# S6E2CCxJ register map
Vendor: Cypress; File version: 2.1
CPU: CM4 r0p1, little endian, MPU, FPU, 4 interrupt priority bits
Registers are 32-bit, read-write, reset 0x0 unless marked. A register's access mark holds for its fields unless they carry their own. Offsets are from the block's base; [hi:lo] are bit positions; {n}, {i} and the like mark numbered series; 'fields as' and 'values as' point back to an identical list.

## ETHERNET_MAC0
Base 0x40064000
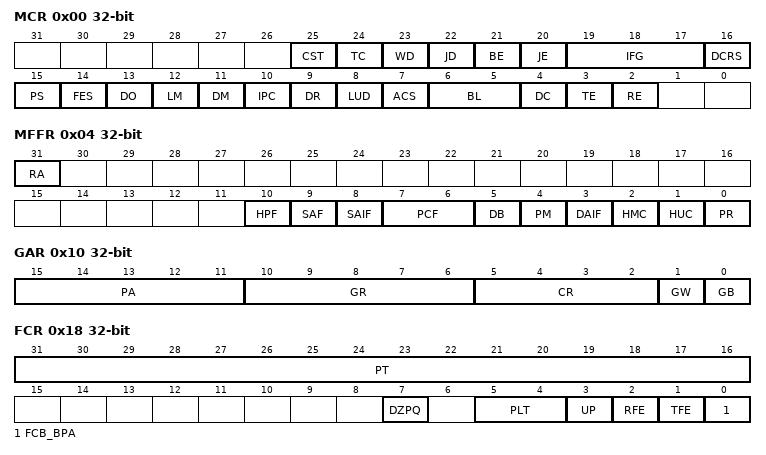
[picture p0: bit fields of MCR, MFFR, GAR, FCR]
0x00 MCR — MAC Configuration Register [BHW]
  [25] CST — CRC stripping for Type frames
  [24] TC — Transmit Configuration in RGMII
  [23] WD — Watchdog Disable
  [22] JD — Jabber Disable
  [21] BE — Frame Burst Enable
  [20] JE — Jumbo Frame Enable
  [19:17] IFG — Inter-Frame GAP
  [16] DCRS — Disable Carrier Sense During Transaction
  [15] PS — Port Select
  [14] FES — Speed
  [13] DO — Disable Receive Own
  [12] LM — Loop-back Mode
  [11] DM — Duplex mode
  [10] IPC — Checksum Offload
  [9] DR — Disable Retry
  [8] LUD — Link Up/Down in RGMII
  [7] ACS — Automatic Pad/CRC Stripping
  [6:5] BL — Back-off Limit
  [4] DC — Deferral Check
  [3] TE — Transmitter Enable
  [2] RE — Receiver Enable
0x04 MFFR — MAC Frame Filter Register [BHW]
  [31] RA — Receive All
  [10] HPF — Hash or Perfect Filter
  [9] SAF — Source Address Filter
  [8] SAIF — Source Address Inverse Filter
  [7:6] PCF — Pass Control Frames
  [5] DB — Disable Broadcast Frames
  [4] PM — Pass All Multicast
  [3] DAIF — DA Inverse Filtering
  [2] HMC — Hash Multicast
  [1] HUC — Hash Unicast
  [0] PR — Promiscuous Mode
0x08 MHTRH — MAC Hash Table Register (High) [BHW]
  [31:0] HTH — the upper 32 bits of the hash table in the HTH
0x0C MHTRL — MAC Hash Table Register (Low) [BHW]
  [31:0] HTL — the lower 32 bits of the hash table in the HTL
0x10 GAR — GMII/MII Address Register [BHW]
  [15:11] PA — Physical Layer Address
  [10:6] GR — GMII Register
  [5:2] CR — Application Clock Range
  [1] GW — GMII/MII Write
  [0] GB — GMII/MII Busy
0x14 GDR — GMII/MII Data Register [BHW]
  [15:0] GD — GMII/MII Data Register
0x18 FCR — Flow Control Register [BHW]
  [31:16] PT — Pause Time
  [7] DZPQ — Disable Zero-Quanta Pause
  [5:4] PLT — Pause Low Threshold
  [3] UP — Unicast Pause Frame detect
  [2] RFE — Receive Flow Control Enable
  [1] TFE — Transmit Flow Control Enable
  [0] FCB_BPA — Flow Control Busy/Backpressure Activate
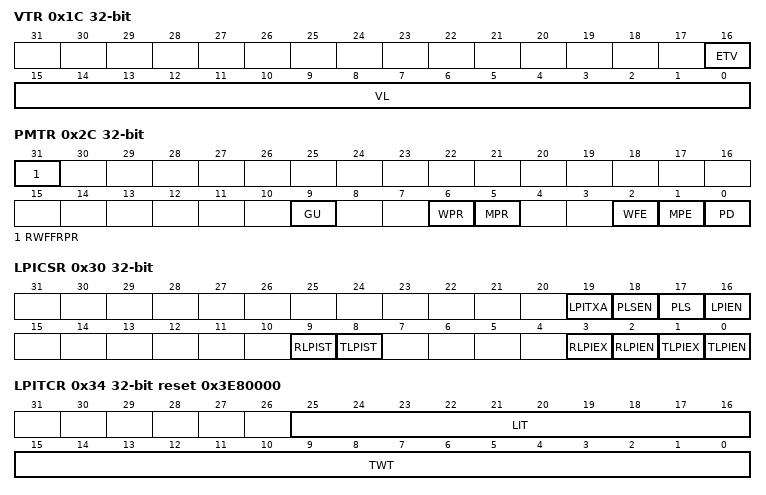
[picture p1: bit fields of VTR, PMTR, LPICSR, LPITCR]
0x1C VTR — VLAN TAG Register [BHW]
  [16] ETV — Enable 12-Bit VLAN Tag Comparison
  [15:0] VL — VLAN Tag Identifier
0x28 RWFFR — Remote Wake-up Frame Filter Register [BHW]
  [31:0] RWFFR — Remote Wake-up Frame Filter Register
0x2C PMTR — PMT Register [BHW]
  [31] RWFFRPR — Remote Wake-up Frame Filter Register Pointer Reset
  [9] GU — Global Unicast
  [6] WPR ro — Wake Up Frame Receive
  [5] MPR ro — Magic Packet Received
  [2] WFE — Wake-Up Frame Enable
  [1] MPE — Magic Packet Enable
  [0] PD — Power Down
0x30 LPICSR — LPI Control and Status Register [BHW]
  [19] LPITXA — LPI TX Automate
  [18] PLSEN — PHY Link Status Enable
  [17] PLS — PHY Link Status
  [16] LPIEN — LPI Enable
  [9] RLPIST ro — Receive LPI State
  [8] TLPIST ro — Transmit LPI State
  [3] RLPIEX ro — Receive LPI Exit
  [2] RLPIEN ro — Receive LPI Entry
  [1] TLPIEX ro — Transmit LPI Exit
  [0] TLPIEN ro — Transmit LPI Entry
0x34 LPITCR reset 0x3E80000 — LPI Timers Control Register [BHW]
  [25:16] LIT — LPI LS TIMER
  [15:0] TWT — LPI TW TIMER
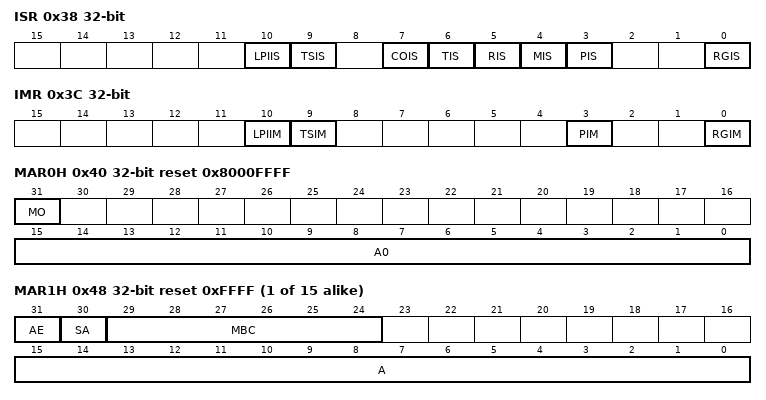
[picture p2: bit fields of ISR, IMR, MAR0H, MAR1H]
0x38 ISR ro — Interrupt Status Register [BHW]
  [10] LPIIS — LPI Interrupt Status
  [9] TSIS — Time Stamp Interrupt Status
  [7] COIS — MMC Receive Checksum Offload Interrupt Status
  [6] TIS — MMC Transmit Interrupt Status
  [5] RIS — MMC Receive Interrupt Status
  [4] MIS — MMC Interrupt Status
  [3] PIS — PMT Interrupt Status
  [0] RGIS — RGMII Interrupt Status
0x3C IMR — Interrupt Mask Register [BHW]
  [10] LPIIM — LPI Interrupt Mask
  [9] TSIM — Time Stamp Interrupt Mask
  [3] PIM — PMT Interrupt Mask
  [0] RGIM — RGMII Interrupt Mask
0x40 MAR0H reset 0x8000FFFF — MAC Address0 Register (High) [BHW]
  [31] MO ro — Must be one
  [15:0] A0 — MAC Address0
0x44 MAR0L reset 0xFFFFFFFF — MAC Address0 Register (Low) [BHW]
  [31:0] A0 — MAC Address0
{0x40+8i} MAR{i}H reset 0xFFFF (i=1..15) — MAC Address{i} Register -High [BHW]
  [31] AE — Address Enable
  [30] SA — Source Address
  [29:24] MBC — Mask Byte Control
  [15:0] A — MAC Address
{0x44+8i} MAR{i}L reset 0xFFFFFFFF (i=1..15) — MAC Address{i} Register -Low [BHW]
  [31:0] A — MAC Address
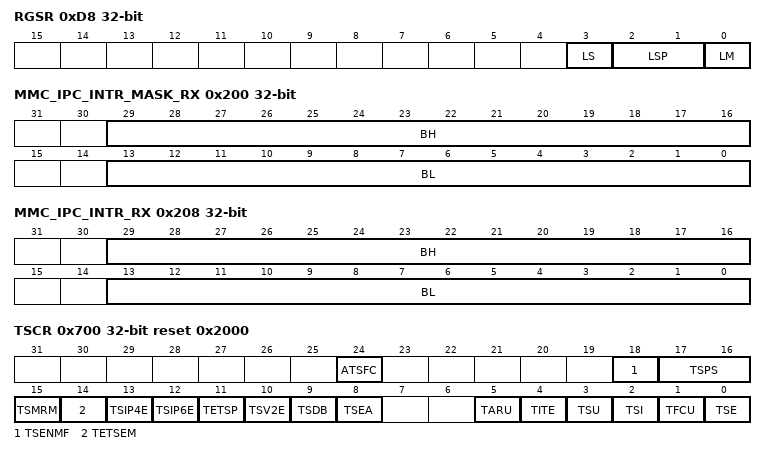
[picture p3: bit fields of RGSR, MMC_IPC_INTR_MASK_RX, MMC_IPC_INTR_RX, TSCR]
0xD8 RGSR ro — RGMII Status Register) [BHW]
  [3] LS — Link Status
  [2:1] LSP — Link Speed
  [0] LM — Link Mode
0x100 MMC_CNTL — MMC Control Register [BHW]
  [5:0] B — Bits of MMC_CNTL
0x104 MMC_INTR_RX ro — Receive Interrupt Register [BHW]
  [23:0] B rw — Bits of MMC_INTR_RX
0x108 MMC_INTR_TX ro — MMC Transmit Interrupt Register [BHW]
  [24:0] B rw — Bits of MMC_INTR_TX
0x10C MMC_INTR_MASK_RX — MMC Receive Interrupt Mask Register [BHW]
  [23:0] B — Bits of MMC_INTR_MASK_RX
0x110 MMC_INTR_MASK_TX — MMC Transmit Interrupt Mask Register [BHW]
  [24:0] B — Bits of MMC_INTR_MASK_TX
0x114 TXOCTETCOUNT_GB ro — Number of bytes transmitted (exclusive of preamble and retried bytes) in good and bad frames [BHW]
0x118 TXFRAMECOUNT_GB ro — Number of good and bad frames transmitted exclusive of retried frames [BHW]
0x11C TXBROADCASTFRAMES_G ro — Number of good broadcast frames transmitted [BHW]
0x120 TXMULTICASTFRAMES_G ro — Number of good multicast frames transmitted[BHW]
0x124 TX64OCTETS_GB ro — Number of good and bad frames transmitted with length of 64 bytes exclusive of preamble and retried frames [BHW]
0x128 TX65TO127OCTETS_GB ro — Number of good and bad frames transmitted with length between 65 and 127 (inclusive) bytes exclusive of preamble and retried frames [BHW]
0x12C TX128TO255OCTETS_GB ro — Number of good and bad frames transmitted with length between 128 and 255 (inclusive) bytes exclusive of preamble and retried frames [BHW]
0x130 TX256TO511OCTETS_GB ro — Number of good and bad frames transmitted with length between 256 and 511 (inclusive) bytes exclusive of preamble and retried frames [BHW]
0x134 TX512TO1023OCTETS_GB ro — Number of good and bad frames transmitted with length between 512 and 1023 (inclusive) bytes exclusive of preamble and retried frames [BHW]
0x138 TX1024TOMAXOCTETS_GB ro — Number of good and bad frames transmitted with length between 1024 and Maxsize (inclusive) bytes exclusive of preamble and retried frames [BHW]
0x13C TXUNICASTFRAMES_GB ro — Number of good and bad unicast frames transmitted [BHW]
0x140 TXMULTICASTFRAMES_GB ro — Number of good and bad multicast frames transmitted [BHW]
0x144 TXBROADCASTFRAMES_GB ro — Number of good and bad broadcast frames transmitted [BHW]
0x148 TXUNDERFLOWERROR ro — Number of frames aborted due to frame underflow error [BHW]
0x14C TXSINGLECOL_G ro — Number of successfully transmitted frames after a single collision in Half-duplex mode [BHW]
0x150 TXMULTICOL_G ro — Number of successfully transmitted frames after more than a single collision in Half-duplex mode [BHW]
0x154 TXDEFERRED ro — Number of successfully transmitted frames after a deferral in Half-duplex mode [BHW]
0x158 TXLATECOL ro — Number of frames aborted due to late collision error [BHW]
0x15C TXEXESSCOL ro — Number of frames aborted due to excessive (16) collision errors [BHW]
0x160 TXCARRIERERROR ro — Number of frames aborted due to carrier sense error (no carrier or loss of carrier). [BHW]
0x164 TXOCTETCOUNT_G ro — Number of bytes transmitted (exclusive of preamble) in good frames only [BHW]
0x168 TXFRAMECOUNT_G ro — Number of good frames transmitted [BHW]
0x16C TXEXECESSDEF_G ro — Number of frames aborted due to excessive deferral error (deferred for more than two max-sized frame times) [BHW]
0x170 TXPAUSEFRAMES ro — Number of good PAUSE frames transmitted [BHW]
0x174 TXVLANFRAMES_G ro — Number of good VLAN frames transmitted exclusive of retried frames [BHW]
0x180 RXFRAMECOUNT_GB ro — Number of good and bad frames received [BHW]
0x184 RXOCTETCOUNT_GB ro — Number of bytes received (exclusive of preamble) in good and bad frames. [BHW]
0x188 RXOCTETCOUNT_G ro — Number of bytes received (exclusive of preamble) only in good frames [BHW]
0x18C RXBROADCASTFRAMES_G ro — Number of good broadcast frames received [BHW]
0x190 RXMULTICASTFRAMES_G ro — Number of good multicast frames received [BHW]
0x194 RXCRCERROR ro — Number of frames received with CRC error[BHW]
0x198 RXALLIGNMENTERROR ro — Number of frames received with alignment (dribble) error. Valid only in 10/100 mode [BHW]
0x19C RXRUNTERROR ro — Number of frames received with runt (64 bytes and CRC error) error [BHW]
0x1A0 RXJABBERERROR ro — Number of frames received with length greater than 1518 bytes with CRC error [BHW]
0x1A4 RXUNDERSIZE_G ro — Number of frames received with length less than 64 bytes without any errors. [BHW]
0x1A8 RXOVERSIZE_G ro — Number of frames received with length greater than the maxsize without error [BHW]
0x1AC RX64OCTETS_GB ro — Number of good and bad frames received with length 64 bytes exclusive of preamble [BHW]
0x1B0 RX65TO127OCTETS_GB ro — Number of good and bad frames received with length between 65 and 127 (inclusive) bytes exclusive of preamble. [BHW]
0x1B4 RX128TO255OCTETS_GB ro — Number of good and bad frames received with length between 128 and 255 (inclusive) bytes exclusive of preamble. [BHW]
0x1B8 RX256TO511OCTETS_GB ro — Number of good and bad frames received with length between 256 and 511 (inclusive) bytes exclusive of preamble. [BHW]
0x1BC RX512TO1023OCTETS_GB ro — Number of good and bad frames received with length between 512 and 1023 (inclusive) bytes exclusive of preamble. [BHW]
0x1C0 RX1024TOMAXOCTETS_GB ro — Number of good and bad frames received with length between 1024 and maxsize (inclusive) bytes exclusive of preamble [BHW]
0x1C4 RXUNICASTFRAMES_G ro — Number of good unicast frames received [BHW]
0x1C8 RXLENGTHERROR ro — Number of frames received with length error (Length type field is not the frame size) for all frames with valid length field [BHW]
0x1CC RXOUTOFRANGETYPE ro — Number of frames received with length/type field not equal to the valid frame size (Greater than 1500) [BHW]
0x1D0 RXPAUSEFRAMES ro — Number of good and valid PAUSE frames received [BHW]
0x1D4 RXFIFOOVERFLOW ro — Number of missed received frames due to FIFO overflow [BHW]
0x1D8 RXVLANFRAMES_GB ro — Number of good and bad VLAN frames received [BHW]
0x1DC RXWATCHDOGERROR ro — Number of frames received with error due to watchdog timeout error (frames with a data load larger than 2048 bytes) [BHW]
0x200 MMC_IPC_INTR_MASK_RX — MMC Receive Checksum Offload Interrupt Mask Register [BHW]
  [29:16] BH — Higher bits of MMC_IPC_INTR_MASK_RX
  [13:0] BL — Lower bits of MMC_IPC_INTR_MASK_RX
0x208 MMC_IPC_INTR_RX ro — MMC Receive Checksum Offload Interrupt Register [BHW]
  [29:16] BH rw — Higher bits of MMC_IPC_INTR_RX
  [13:0] BL rw — Lower bits of MMC_IPC_INTR_RX
0x210 RXIPV4_GD_FRMS ro — Number of good IPv4 datagrams received with the TCP/UDP or ICMP payload [BHW]
0x214 RXIPV4_HDRERR_FRMS ro — Number of IPv4 datagrams received with header errors (checksum/length or version mismatch) [BHW]
0x218 RXIPV4_NOPAY_FRMS ro — Number of IPv4 datagram frames received that did not have a TCP/UDP or ICMP payload processed by the Checksum engine [BHW]
0x21C RXIPV4_FRAG_FRMS ro — Number of good IPv4 datagrams with fragmentation [BHW]
0x220 RXIPV4_UDSBL_FRMS ro — Number of good IPv4 datagrams received that had a UDP payload with checksum disabled [BHW]
0x224 RXIPV6_GD_FRMS ro — Number of good IPv6 datagrams received with TCP/UDP or ICMP payloads [BHW]
0x228 RXIPV6_HDRERR_FRMS ro — Number of IPv6 datagrams received with header errors (length or version mismatch) [BHW]
0x22C RXIPV6_NOPAY_FRMS ro — Number of IPv6 datagram frames received that did not have a TCP/UDP or ICMP payload. This includes all IPv6 datagrams with fragmentation or security extension headers [BHW]
0x230 RXUDP_GD_FRMS ro — Number of good IP datagrams with a good UDP payload. This counter is not updated when the rxipv4_udsbl_frms counter is incremented [BHW]
0x234 RXUDP_ERR_FRMS ro — Number of good IP datagrams whose UDP payload has a checksum error [BHW]
0x238 RXTCP_GD_FRMS ro — Number of good IP datagrams with a good TCP payload [BHW]
0x23C RXTCP_ERR_FRMS ro — Number of good IP datagrams whose TCP payload has a checksum error [BHW]
0x240 RXICMP_GD_FRMS ro — Number of good IP datagrams with a good ICMP payload [BHW]
0x244 RXICMP_ERR_FRMS ro — Number of good IP datagrams whose ICMP payload has a checksum error [BHW]
0x250 RXIPV4_GD_OCTETS ro — Number of bytes received in good IPv4 datagrams encapsulating TCP/UDP or ICMP data. (Ethernet header/FCS/pad or IP pad bytes are not included in this counter or in the octet counters listed below). [BHW]
0x254 RXIPV4_HDRERR_OCTETS ro — Number of bytes received in IPv4 datagrams with header errors (checksum/length version mismatch). The value in the Length field of IPv4 header is used to update this counter [BHW]
0x258 RXIPV4_NOPAY_OCTETS ro — Number of bytes received in IPv4 datagrams that did not have a TCP/UDP or ICMP payload. The value in the IPv4 header's Length field is used to update this counter [BHW]
0x25C RXIPV4_FRAG_OCTETS ro — Number of bytes received in fragmented IPv4 datagrams. The value in the IPv4 header's Length field is used to update this counter [BHW]
0x260 RXIPV4_UDSBL_OCTETS ro — Number of bytes received in a UDP segment that had the UDP checksum disabled. This counter does not count IP Header bytes [BHW]
0x264 RXIPV6_GD_OCTETS ro — Number of bytes received in good IPv6 datagrams encapsulating TCP/UDP or ICMPv6 data [BHW]
0x268 RXIPV6_HDRERR_OCTETS ro — Number of bytes received in IPv6 datagrams with header errors (length/version mismatch). The value in the IPv6 header's Length field is used to update this counter. [BHW]
0x26C RXIPV6_NOPAY_OCTETS ro — Number of bytes received in IPv6 datagrams that did not have a TCP/UDP or ICMP payload. The value in the IPv6 header's Length field is used to update this counter [BHW]
0x270 RXUDP_GD_OCTETS ro — Number of bytes received in a good UDP segment. This counter (and the counters below) does not count IP header bytes [BHW]
0x274 RXUDP_ERR_OCTETS ro — Number of bytes received in a UDP segment that had checksum errors [BHW]
0x278 RXTCP_GD_OCTETS ro — Number of bytes received in a good TCP segment [BHW]
0x27C RXTCP_ERR_OCTETS ro — Number of bytes received in a TCP segment with checksum errors [BHW]
0x280 RXICMP_GD_OCTETS ro — Number of bytes received in a good ICMP segment [BHW]
0x284 RXICMP_ERR_OCTETS ro — Number of bytes received in an ICMP segment with checksum errors [BHW]
0x700 TSCR reset 0x2000 — Time Stamp Control Register [BHW]
  [24] ATSFC — Auxiliary Snapshot FIFO Clear
  [18] TSENMF — Enable MAC address for PTP frame filtering
  [17:16] TSPS — SelectPTP packets for taking snapshots
  [15] TSMRM — Enable Snapshot for Messages Relevant to Master
  [14] TETSEM — Enable Time Stamp Snapshot for Event Messages
  [13] TSIP4E — Enable Time Stamp Snapshot for IPv4 frames
  [12] TSIP6E — Enable Time Stamp Snapshot for IPv6 frames
  [11] TETSP — Enable Time Stamp Snapshot for PTP over Ethernet frames
  [10] TSV2E — Enable PTP packet snooping for version 2 format
  [9] TSDB — Time Stamp Digital or Binary rollover control
  [8] TSEA — Enable Time Stamp for All Frames
  [5] TARU — Addend Register Update
  [4] TITE — Time Stamp Interrupt Trigger Enable
  [3] TSU — Time Stamp Update
  [2] TSI — Time Stamp Initialize
  [1] TFCU — Time Stamp Fine or Coarse Update
  [0] TSE — Time Stamp Enable
0x704 SSIR — Sub-Second Increment Register [BHW]
  [7:0] SSINC — Sub-Second Increment Value
0x708 STSR ro — System Time - Seconds Register [BHW]
  [31:0] TSS — Time Stamp Second
0x70C STNR ro — System Time - Nanoseconds Register [BHW]
  [30:0] TSSS — Time Stamp Sub-Seconds
0x710 STSUR — System Time - Seconds Update Register [BHW]
  [31:0] TSS — Time Stamp Second
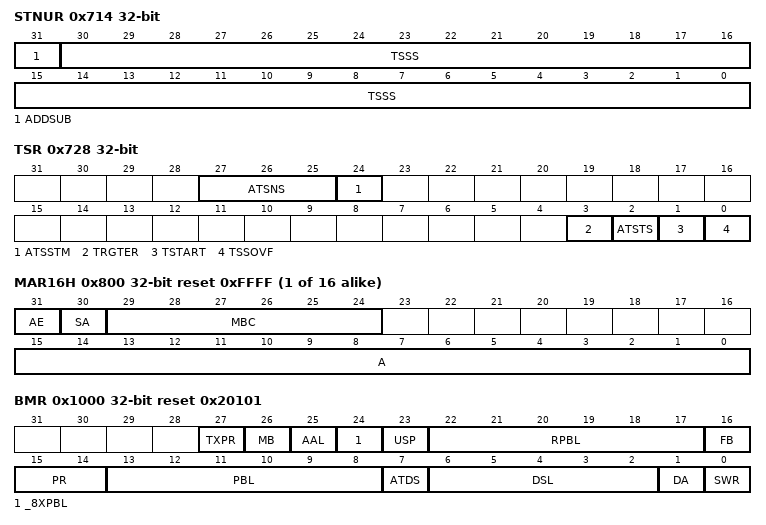
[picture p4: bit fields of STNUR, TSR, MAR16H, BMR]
0x714 STNUR — System Time - Nanoseconds Update Register [BHW]
  [31] ADDSUB — Add or Subtract Time
  [30:0] TSSS — Time Stamp Sub-Seconds
0x718 TSAR — Time Stamp Addend Register [BHW]
  [31:0] TSAR — Time Stamp Addend Register
0x71C TTSR — Target Time Seconds Register [BHW]
  [31:0] TSTR — Target Time Stamp Seconds Register
0x720 TTNR — Target Time Nanoseconds Register [BHW]
  [30:0] TSTR — Target Time Stamp Nanoseconds Register
0x724 STHWSR — System Time - Higher Word Seconds Register [BHW]
  [15:0] TSHWR — Time Stamp Higher Word Register
0x728 TSR ro — Time Stamp Status Register [BHW]
  [27:25] ATSNS — Auxiliary Time Stamp Number of Snapshots
  [24] ATSSTM — Auxiliary Time Stamp Snapshot Trigger Missed
  [3] TRGTER — Timestamp Target Time Error
  [2] ATSTS — Auxiliary Time Stamp Trigger Snapshot
  [1] TSTART — Time Stamp Target Time Reached
  [0] TSSOVF — Time Stamp Seconds Overflow
0x72C PPSCR — PPS Control Register [BHW]
  [3:0] PPSCTRL — Controls the frequency of the PPS output
0x730 ATNR ro — Auxiliary Time Stamp - Nanoseconds Register [BHW]
  [30:0] ATN
0x734 ATSR ro — Auxiliary Time Stamp - Seconds Register [BHW]
  [31:0] ATS
{0x780+8i} MAR{i}H reset 0xFFFF (i=16..31) — MAC Address{i} Register -High [BHW]
  fields as MAR1H
{0x784+8i} MAR{i}L reset 0xFFFFFFFF (i=16..31) — MAC Address{i} Register -Low [BHW]
  [31:0] A — MAC Address
0x1000 BMR reset 0x20101 — Bus Mode Register [BHW]
  [27] TXPR — Transmit Priority
  [26] MB — Mixed Burst
  [25] AAL — Address-Aligned Beats
  [24] _8XPBL — 8xPBL Mode
  [23] USP — Use Separate PBL
  [22:17] RPBL — RxDMA PBL
  [16] FB — Fixed Burst
  [15:14] PR — Rx:Tx priority ratio
  [13:8] PBL — Programmable Burst Length
  [7] ATDS — Alternate Descriptor Size
  [6:2] DSL — Descriptor Skip Length
  [1] DA — DMA Arbitration scheme
  [0] SWR — Software Reset
0x1004 TPDR — Transmit Poll Demand Register) [BHW]
  [31:0] TPD — Transmit Poll Demand
0x1008 RPDR — Receive Poll Demand Register [BHW]
  [31:0] RPD — Receive Poll Demand
0x100C RDLAR — Receive Descriptor List Address Register) [BHW]
  [31:2] SRL — Start of Receive List
0x1010 TDLAR — Transmit Descriptor List Address Register [BHW]
  [31:2] STL — Start of Transmit List
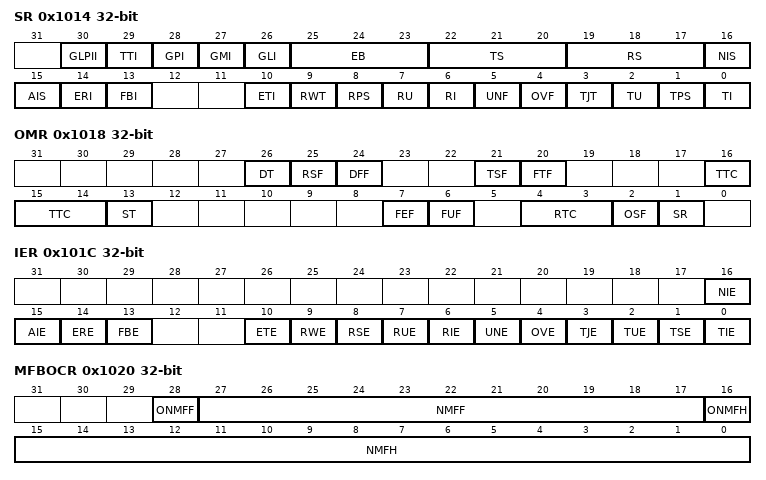
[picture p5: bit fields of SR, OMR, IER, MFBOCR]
0x1014 SR — Status Register [BHW]
  [30] GLPII ro — GMAC LPI Interrupt
  [29] TTI ro — Time-Stamp Trigger Interrupt
  [28] GPI ro — GMAC PMT Interrupt
  [27] GMI ro — GMAC MMC Interrupt
  [26] GLI ro — GMAC Line interface Interrupt
  [25:23] EB ro — Error Bits
  [22:20] TS ro — Transmit Process State
  [19:17] RS ro — Receive Process State
  [16] NIS ro — Normal Interrupt Summary
  [15] AIS ro — Abnormal Interrupt Summary
  [14] ERI ro — Early Receive Interrupt
  [13] FBI ro — Fatal Bus Error Interrupt
  [10] ETI ro — Early Transmit Interrupt
  [9] RWT ro — Receive Watchdog Timeout
  [8] RPS ro — Receive process Stopped
  [7] RU ro — Receive Buffer Unavailable
  [6] RI ro — Receive Interrupt
  [5] UNF ro — Transmit underflow
  [4] OVF ro — Receive Overflow
  [3] TJT ro — Transmit Jabber Timeout
  [2] TU ro — Transmit Buffer Unavailable
  [1] TPS ro — Transmit Process Stopped
  [0] TI ro — Transmit Interrupt
0x1018 OMR — Operation Mode Register [BHW]
  [26] DT — Disable Dropping of TCP/IP Checksum Error Frames
  [25] RSF — Receive Store and Forward
  [24] DFF — Disable Flushing of Received Frames
  [21] TSF — Transmit Store Forward
  [20] FTF — Flush Transmit FIFO
  [16:14] TTC — Transmit Threshold Control
  [13] ST — Start/Stop Transmission Command
  [7] FEF — Forward Error Frames
  [6] FUF — Forward Undersized Good Frames
  [4:3] RTC — Receive Threshold Control
  [2] OSF — Operate on Second Frame
  [1] SR — Start/Stop Receive
0x101C IER — Interrupt Enable Register [BHW]
  [16] NIE — Normal Interrupt Summary Enable
  [15] AIE — Abnormal Interrupt Summary Enable
  [14] ERE — Early Receive Interrupt Enable
  [13] FBE — Fatal Bus Error Enable
  [10] ETE — Early Transmit Interrupt Enable
  [9] RWE — Receive Watchdog Timeout Enable
  [8] RSE — Receive Process Stopped Enable
  [7] RUE — Receive Buffer Unavailable Enable
  [6] RIE — Receive Interrupt Enable
  [5] UNE — Transmit underflow Enable
  [4] OVE ro — Receive Overflow Enable
  [3] TJE — Transmit Jabber Timeout
  [2] TUE — Transmit Buffer Unavailable
  [1] TSE — Transmit Process Stopped
  [0] TIE — Transmit Interrupt
0x1020 MFBOCR ro — Missed Frame and Buffer Overflow Counter Register [BHW]
  [28] ONMFF — Overflow NMFF
  [27:17] NMFF — Number of Missed frame by Ethernet-MAC
  [16] ONMFH — Overflow NMFH
  [15:0] NMFH — Number of Missed frame by HOST
0x1024 RIWTR — Receive Interrupt Watchdog Timer Register [BHW]
  [7:0] RIWT ro — RI Watchdog Timer count
0x102C AHBSR ro — AHB Status Register [BHW]
  [0] AHBS — AHB Status
0x1048 CHTDR ro — Current Host Transmit Descriptor Register [BHW]
  [31:0] HTDAP — Host Transmit Descriptor Address Pointer
0x104C CHRDR ro — Current Host Receive Descriptor Register [BHW]
  [31:0] HRDAP — Host Receive Descriptor Address Pointer
0x1050 CHTBAR ro — Current Host Transmit Buffer Address Register [BHW]
  [31:0] HTBAR — Host Transmit Buffer Address Register
0x1054 CHRBAR ro — Current Host Receive Buffer Address Register [BHW]
  [31:0] HRBAR — Host Receive Buffer Address Register

## Notices in the file
Copyright (C) 2013-2016, Cypress Semiconductor Corporation or a
subsidiary of Cypress Semiconductor Corporation.  All rights reserved.
This software, including source code, documentation and related
materials ("Software"), is owned by Cypress Semiconductor Corporation or
one of its subsidiaries ("Cypress") and is protected by and subject to
worldwide patent protection (United States and foreign), United States
copyright laws and international treaty provisions. Therefore, you may use
this Software only as provided in the license agreement accompanying the
software package from which you obtained this Software ("EULA").
If no EULA applies, Cypress hereby grants you a personal, non-exclusive,
non-transferable license to copy, modify, and compile the
Software source code solely for use in connection with Cypress's
integrated circuit products.  Any reproduction, modification, translation,
compilation, or representation of this Software except as specified
above is prohibited without the express written permission of Cypress.
Disclaimer: THIS SOFTWARE IS PROVIDED AS-IS, WITH NO
WARRANTY OF ANY KIND, EXPRESS OR IMPLIED, INCLUDING,
BUT NOT LIMITED TO, NONINFRINGEMENT, IMPLIED
WARRANTIES OF MERCHANTABILITY AND FITNESS FOR A
PARTICULAR PURPOSE. Cypress reserves the right to make
changes to the Software without notice. Cypress does not assume any
liability arising out of the application or use of the Software or any
product or circuit described in the Software. Cypress does not
authorize its products for use in any products where a malfunction or
failure of the Cypress product may reasonably be expected to result in
significant property damage, injury or death ("High Risk Product"). By
including Cypress's product in a High Risk Product, the manufacturer
of such system or application assumes all risk of such use and in doing
so agrees to indemnify Cypress against all liability.
